VERSION ""

NS_ :

BS_:

BU_: VCU RSM

BO_ 3221225472 VECTOR__INDEPENDENT_SIG_MSG: 0 Vector__XXX
 SG_ AT_Life_Counter_1 : 32|16@1+ (1,0) [0|0] "" Vector__XXX
 SG_ AT_Life_Counter_2 : 48|16@1+ (1,0) [0|0] "" Vector__XXX
 SG_ Current_SW_10 : 48|16@1+ (0.00125,0) [0|10.3226] "A" Vector__XXX
 SG_ PWM_SW_10 : 48|16@1+ (0.01,0) [0|100] "%" Vector__XXX

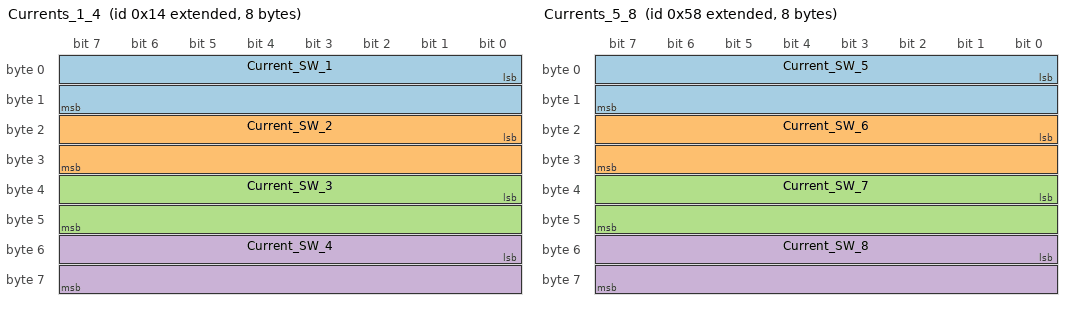
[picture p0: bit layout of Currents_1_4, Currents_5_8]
BO_ 2147483668 Currents_1_4: 8 RSM
 SG_ Current_SW_1 : 0|16@1+ (0.00125,0) [0|10.3226] "A" Vector__XXX
 SG_ Current_SW_2 : 16|16@1+ (0.00125,0) [0|10.3226] "A" Vector__XXX
 SG_ Current_SW_3 : 32|16@1+ (0.00125,0) [0|10.3226] "A" Vector__XXX
 SG_ Current_SW_4 : 48|16@1+ (0.00125,0) [0|10.3226] "A" Vector__XXX

BO_ 2147483736 Currents_5_8: 8 RSM
 SG_ Current_SW_5 : 0|16@1+ (0.00125,0) [0|10.3226] "A" Vector__XXX
 SG_ Current_SW_6 : 16|16@1+ (0.00125,0) [0|10.3226] "A" Vector__XXX
 SG_ Current_SW_7 : 32|16@1+ (0.00125,0) [0|10.3226] "A" Vector__XXX
 SG_ Current_SW_8 : 48|16@1+ (0.00125,0) [0|10.3226] "A" Vector__XXX

BO_ 2147483657 Currents_9: 8 RSM
 SG_ Current_SW_9 : 0|16@1+ (0.00125,0) [0|10.3226] "A" Vector__XXX

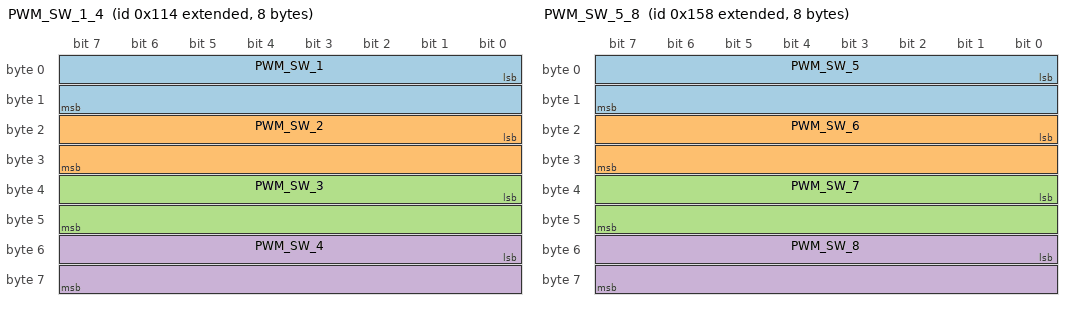
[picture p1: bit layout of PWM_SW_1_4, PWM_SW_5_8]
BO_ 2147483924 PWM_SW_1_4: 8 VCU
 SG_ PWM_SW_1 : 0|16@1+ (0.01,0) [0|100] "%" Vector__XXX
 SG_ PWM_SW_2 : 16|16@1+ (0.01,0) [0|100] "%" Vector__XXX
 SG_ PWM_SW_3 : 32|16@1+ (0.01,0) [0|100] "%" Vector__XXX
 SG_ PWM_SW_4 : 48|16@1+ (0.01,0) [0|100] "%" Vector__XXX

BO_ 2147483992 PWM_SW_5_8: 8 VCU
 SG_ PWM_SW_5 : 0|16@1+ (0.01,0) [0|100] "%" Vector__XXX
 SG_ PWM_SW_6 : 16|16@1+ (0.01,0) [0|100] "%" Vector__XXX
 SG_ PWM_SW_7 : 32|16@1+ (0.01,0) [0|100] "%" Vector__XXX
 SG_ PWM_SW_8 : 48|16@1+ (0.01,0) [0|100] "%" Vector__XXX

BO_ 2147483913 PWM_SW_9: 8 VCU
 SG_ PWM_SW_9 : 0|16@1+ (0.01,0) [0|100] "%" Vector__XXX
